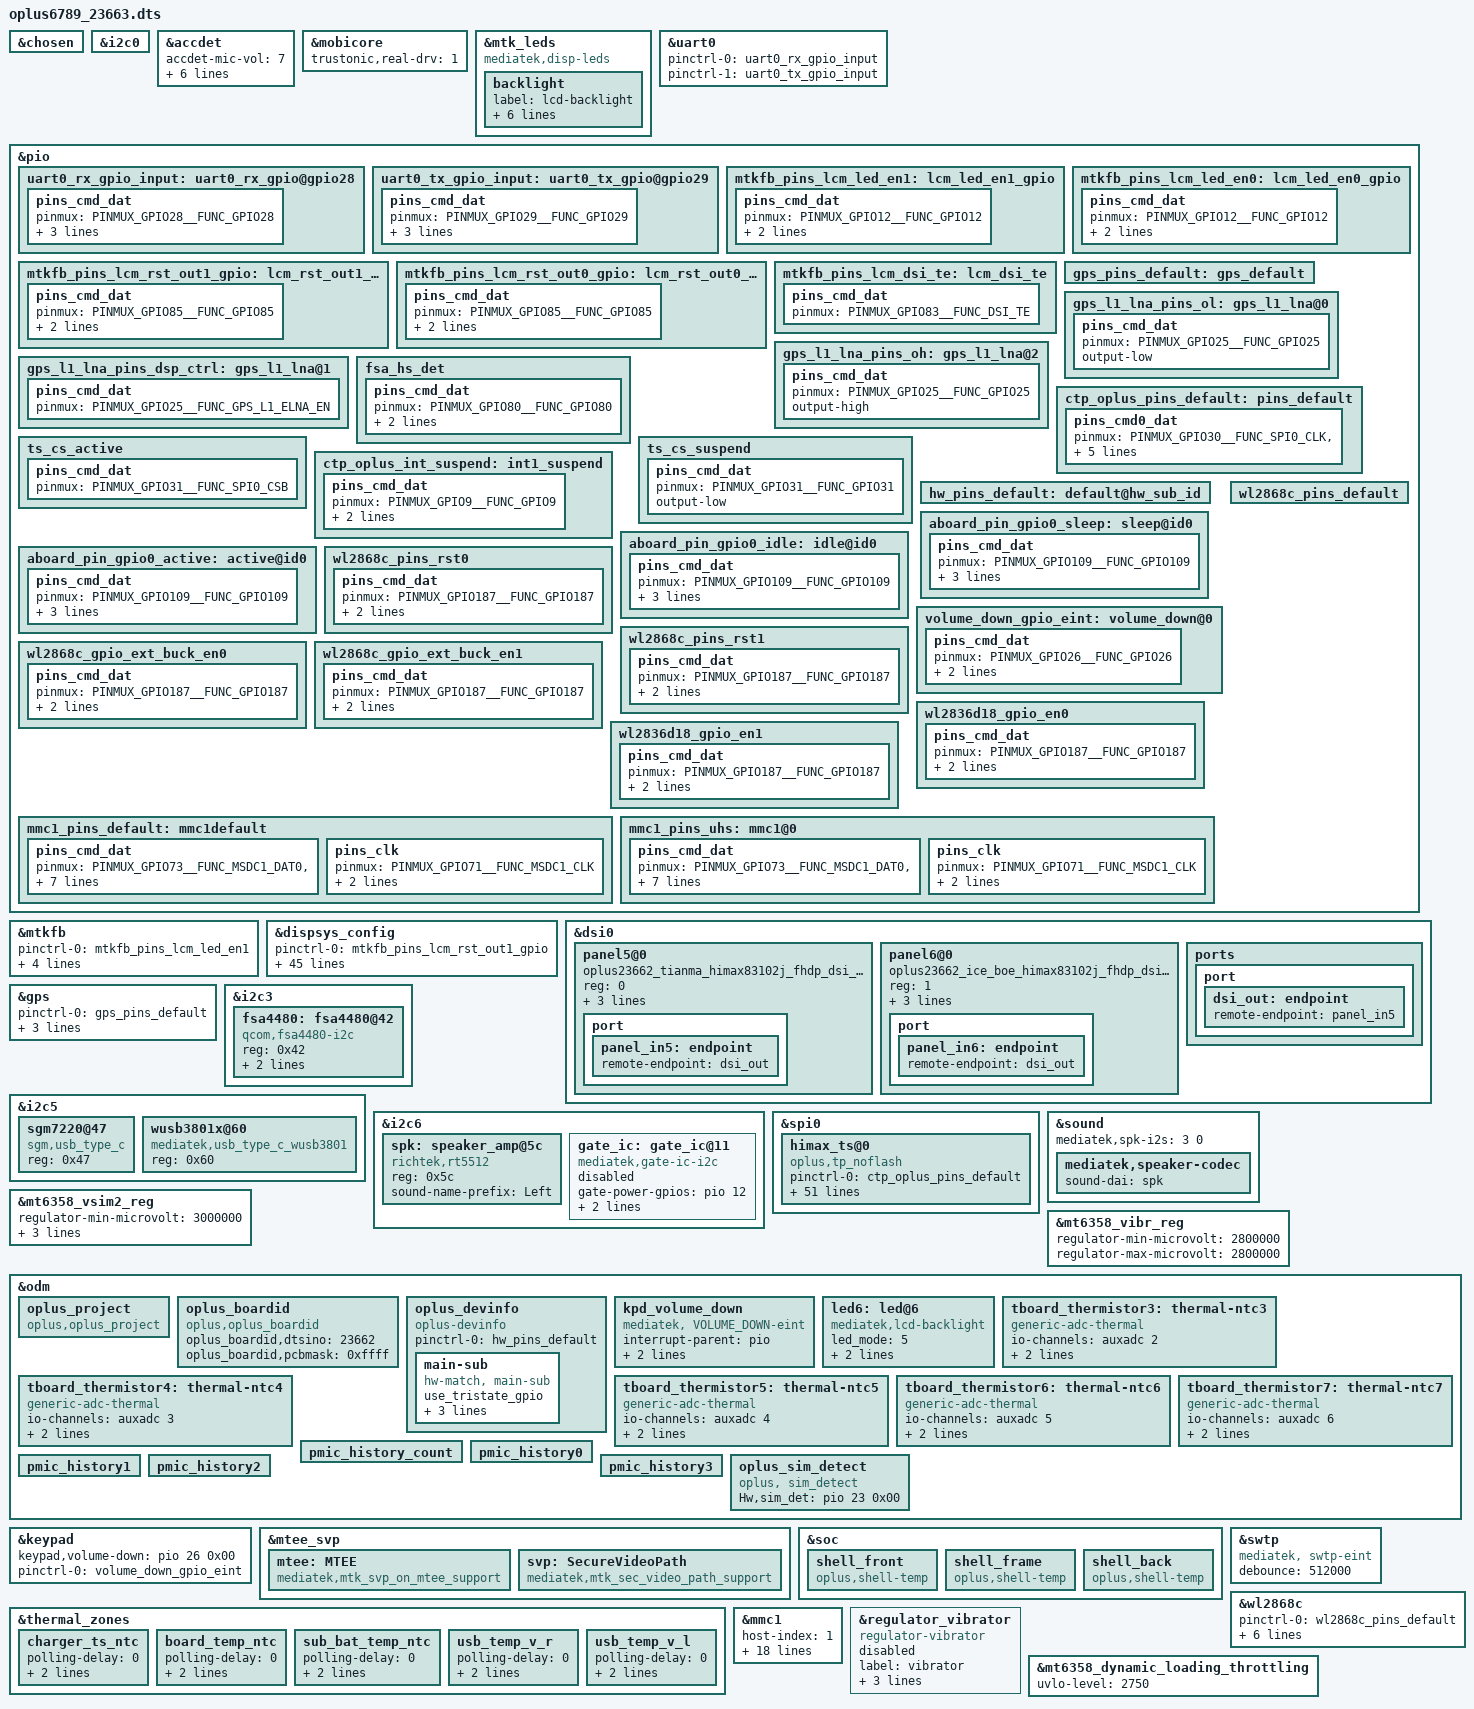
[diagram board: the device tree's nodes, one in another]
// SPDX-License-Identifier: (GPL-2.0 OR MIT)
/*
 * Copyright (C) 2021 MediaTek Inc.
 */
/dts-v1/;
/plugin/;
#include <dt-bindings/interrupt-controller/arm-gic.h>
#include <dt-bindings/interrupt-controller/irq.h>
#include <dt-bindings/pinctrl/mt6789-pinfunc.h>
#include "mediatek/cust_mt6789_camera_sonic.dtsi"
#include "mediatek/mt6789-sia810x.dtsi"
#include "mediatek/oplus6789_charger_23662.dtsi"
#include "mediatek/oplus_sensor_23662.dtsi"

&chosen {

};

&i2c0 {
	status = "okay";

};

/* accdet start */
&accdet {
    /* accdet micbias voltage: 0x07,2.7v;0x05,2.5v;0x02,1.9v */
    accdet-mic-vol = <7>;
    /* accdet pwm_width, pwm_thresh, fall_delay, rise_delay
     * debounce0, debounce1, debounce3, debounce4
     * eint pwm_width, eint pwm_thresh
     * eint deb(debounce0, debounce1, debounce2, debounce3), inv_debounce
     */
    headset-mode-setting = <0x500 0x500 1 0x1f0
                0x800 0x800 0x20 0x44
                0x4 0x1
                0x5 0x3 0x3 0x5 0xe>;
    accdet-plugout-debounce = <1>;
    /*0--MD_MAX--UP_MAX--DW_MAX*/
    headset-three-key-threshold = <0 82 170 400>;
    headset-three-key-threshold-CDD = <0 121 192 600>;
    /*0--MD_MAX--VOICE_MAX--UP_MAX--DW_MAX*/
    headset-four-key-threshold = <0 58 121 192 400>;
    status = "okay";
};
/* accdet end */

/*start tee*/
&mobicore {
	trustonic,real-drv = <1>;
};
/*end tee*/

&mtk_leds {
	compatible = "mediatek,disp-leds";
	backlight {
		label = "lcd-backlight";
		led_mode = <4>;
		max-brightness = <4095>;
		max-hw-brightness = <4095>;
		led-bits = <12>;
		trans-bits = <12>;
		default-state = "on";
	};
};

&uart0 {
	pinctrl-names = "uart0_rx_gpio",
		"uart0_tx_gpio";
	pinctrl-0 = <&uart0_rx_gpio_input>;
	pinctrl-1 = <&uart0_tx_gpio_input>;
	status = "okay";
};

&pio {
	uart0_rx_gpio_input:uart0_rx_gpio@gpio28 {
		pins_cmd_dat {
			pinmux = <PINMUX_GPIO28__FUNC_GPIO28>;
			input-enable;
			slew-rate = <0>;
			bias-pull-down;
		};
	};

	uart0_tx_gpio_input:uart0_tx_gpio@gpio29 {
		pins_cmd_dat {
			pinmux = <PINMUX_GPIO29__FUNC_GPIO29>;
			input-enable;
			slew-rate = <0>;
			bias-pull-down;
		};
	};
};

&pio {
	mtkfb_pins_lcm_led_en1: lcm_led_en1_gpio {
		pins_cmd_dat {
			pinmux = <PINMUX_GPIO12__FUNC_GPIO12>;
			slew-rate = <1>;
			output-high;
		};
	};

	mtkfb_pins_lcm_led_en0: lcm_led_en0_gpio {
		pins_cmd_dat {
			pinmux = <PINMUX_GPIO12__FUNC_GPIO12>;
			slew-rate = <1>;
			output-low;
		};
	};

	mtkfb_pins_lcm_rst_out1_gpio: lcm_rst_out1_gpio {
		pins_cmd_dat {
			pinmux = <PINMUX_GPIO85__FUNC_GPIO85>;
			slew-rate = <1>;
			output-high;
		};
	};

	mtkfb_pins_lcm_rst_out0_gpio: lcm_rst_out0_gpio {
		pins_cmd_dat {
			pinmux = <PINMUX_GPIO85__FUNC_GPIO85>;
			slew-rate = <1>;
			output-low;
		};
	};
	mtkfb_pins_lcm_dsi_te: lcm_dsi_te {
		pins_cmd_dat {
			pinmux = <PINMUX_GPIO83__FUNC_DSI_TE>;
		};
	};
};

&mtkfb {
	pinctrl-names = "lcm_led_en1_gpio", "lcm_led_en0_gpio",
		"lcm_rst_out1_gpio", "lcm_rst_out0_gpio",
		"mode_te_te";
	pinctrl-0 = <&mtkfb_pins_lcm_led_en1>;
	pinctrl-1 = <&mtkfb_pins_lcm_led_en0>;
	pinctrl-2 = <&mtkfb_pins_lcm_rst_out1_gpio>;
	pinctrl-3 = <&mtkfb_pins_lcm_rst_out0_gpio>;
	pinctrl-4 = <&mtkfb_pins_lcm_dsi_te>;
	status = "okay";
};

&dispsys_config {
	pinctrl-names =
		"lcm_rst_out1_gpio", "lcm_rst_out0_gpio",
		"mode_te_te";
	pinctrl-0 = <&mtkfb_pins_lcm_rst_out1_gpio>;
	pinctrl-1 = <&mtkfb_pins_lcm_rst_out0_gpio>;
	pinctrl-2 = <&mtkfb_pins_lcm_dsi_te>;
	status = "okay";

    helper-name = "MTK_DRM_OPT_STAGE",
            "MTK_DRM_OPT_USE_CMDQ",
            "MTK_DRM_OPT_USE_M4U",
            "MTK_DRM_OPT_MMQOS_SUPPORT",
            "MTK_DRM_OPT_MMDVFS_SUPPORT",
            "MTK_DRM_OPT_SODI_SUPPORT",
            "MTK_DRM_OPT_IDLE_MGR",
            "MTK_DRM_OPT_IDLEMGR_SWTCH_DECOUPLE",
            "MTK_DRM_OPT_IDLEMGR_BY_REPAINT",
            "MTK_DRM_OPT_IDLEMGR_ENTER_ULPS",
            "MTK_DRM_OPT_IDLEMGR_KEEP_LP11",
            "MTK_DRM_OPT_DYNAMIC_RDMA_GOLDEN_SETTING",
            "MTK_DRM_OPT_IDLEMGR_DISABLE_ROUTINE_IRQ",
            "MTK_DRM_OPT_MET_LOG",
            "MTK_DRM_OPT_USE_PQ",
            "MTK_DRM_OPT_ESD_CHECK_RECOVERY",
            "MTK_DRM_OPT_ESD_CHECK_SWITCH",
            "MTK_DRM_OPT_PRESENT_FENCE",
            "MTK_DRM_OPT_RDMA_UNDERFLOW_AEE",
            "MTK_DRM_OPT_DSI_UNDERRUN_AEE",
            "MTK_DRM_OPT_HRT",
            "MTK_DRM_OPT_HRT_MODE",
            "MTK_DRM_OPT_DELAYED_TRIGGER",
            "MTK_DRM_OPT_OVL_EXT_LAYER",
            "MTK_DRM_OPT_AOD",
            "MTK_DRM_OPT_RPO",
            "MTK_DRM_OPT_DUAL_PIPE",
            "MTK_DRM_OPT_PAPER_MODE",
            "MTK_DRM_OPT_DC_BY_HRT",
            "MTK_DRM_OPT_OVL_WCG",
            "MTK_DRM_OPT_OVL_SBCH",
            "MTK_DRM_OPT_COMMIT_NO_WAIT_VBLANK",
            "MTK_DRM_OPT_MET",
            "MTK_DRM_OPT_REG_PARSER_RAW_DUMP",
            "MTK_DRM_OPT_VP_PQ",
            "MTK_DRM_OPT_GAME_PQ",
            "MTK_DRM_OPT_MMPATH",
            "MTK_DRM_OPT_HBM",
            "MTK_DRM_OPT_VDS_PATH_SWITCH",
            "MTK_DRM_OPT_LAYER_REC",
            "MTK_DRM_OPT_CLEAR_LAYER",
            "MTK_DRM_OPT_LFR",
            "MTK_DRM_OPT_SF_PF",
            "MTK_DRM_OPT_DYN_MIPI_CHANGE",
            "MTK_DRM_OPT_PRIM_DUAL_PIPE",
            "MTK_DRM_OPT_MSYNC2_0",
            "MTK_DRM_OPT_VIRTUAL_DISP",
            "MTK_DRM_OPT_MML_PRIMARY";

    helper-value = <0>, /*MTK_DRM_OPT_STAGE*/
            <1>, /*MTK_DRM_OPT_USE_CMDQ*/
            <1>, /*MTK_DRM_OPT_USE_M4U*/
            <1>, /*MTK_DRM_OPT_MMQOS_SUPPORT*/
            <1>, /*MTK_DRM_OPT_MMDVFS_SUPPORT*/
            <0>, /*MTK_DRM_OPT_SODI_SUPPORT*/
            <1>, /*MTK_DRM_OPT_IDLE_MGR*/
            <0>, /*MTK_DRM_OPT_IDLEMGR_SWTCH_DECOUPLE*/
            <1>, /*MTK_DRM_OPT_IDLEMGR_BY_REPAINT*/
            <0>, /*MTK_DRM_OPT_IDLEMGR_ENTER_ULPS*/
            <0>, /*MTK_DRM_OPT_IDLEMGR_KEEP_LP11*/
            <0>, /*MTK_DRM_OPT_DYNAMIC_RDMA_GOLDEN_SETTING*/
            <1>, /*MTK_DRM_OPT_IDLEMGR_DISABLE_ROUTINE_IRQ*/
            <0>, /*MTK_DRM_OPT_MET_LOG*/
            <1>, /*MTK_DRM_OPT_USE_PQ*/
            <1>, /*MTK_DRM_OPT_ESD_CHECK_RECOVERY*/
            <1>, /*MTK_DRM_OPT_ESD_CHECK_SWITCH*/
            <1>, /*MTK_DRM_OPT_PRESENT_FENCE*/
            <0>, /*MTK_DRM_OPT_RDMA_UNDERFLOW_AEE*/
            <1>, /*MTK_DRM_OPT_DSI_UNDERRUN_AEE*/
            <1>, /*MTK_DRM_OPT_HRT*/
            <1>, /*MTK_DRM_OPT_HRT_MODE*/
            <0>, /*MTK_DRM_OPT_DELAYED_TRIGGER*/
            <1>, /*MTK_DRM_OPT_OVL_EXT_LAYER*/
            <0>, /*MTK_DRM_OPT_AOD*/
            <1>, /*MTK_DRM_OPT_RPO*/
            <0>, /*MTK_DRM_OPT_DUAL_PIPE*/
            <1>, /*MTK_DRM_OPT_PAPER_MODE*/
            <0>, /*MTK_DRM_OPT_DC_BY_HRT*/
            <0>, /*MTK_DRM_OPT_OVL_WCG*/
            <0>, /*MTK_DRM_OPT_OVL_SBCH*/
            <1>, /*MTK_DRM_OPT_COMMIT_NO_WAIT_VBLANK*/
            <0>, /*MTK_DRM_OPT_MET*/
            <0>, /*MTK_DRM_OPT_REG_PARSER_RAW_DUMP*/
            <0>, /*MTK_DRM_OPT_VP_PQ*/
            <0>, /*MTK_DRM_OPT_GAME_PQ*/
            <0>, /*MTK_DRM_OPT_MMPATH*/
            <0>, /*MTK_DRM_OPT_HBM*/
            <0>, /*MTK_DRM_OPT_VDS_PATH_SWITCH*/
            <0>, /*MTK_DRM_OPT_LAYER_REC*/
            <1>, /*MTK_DRM_OPT_CLEAR_LAYER*/
            <1>, /*MTK_DRM_OPT_LFR*/
            <0>, /*MTK_DRM_OPT_SF_PF*/
            <1>, /*MTK_DRM_OPT_DYN_MIPI_CHANGE*/
            <0>, /*MTK_DRM_OPT_PRIM_DUAL_PIPE*/
            <0>, /*MTK_DRM_OPT_MSYNC2_0*/
            <0>, /*MTK_DRM_OPT_VIRTUAL_DISP*/
            <0>; /*MTK_DRM_OPT_MML_PRIMARY*/
};

&dsi0 {
	status = "okay";
	#address-cells = <1>;
	#size-cells = <0>;
	panel5@0 {
		compatible = "oplus23662_tianma_himax83102j_fhdp_dsi_vdo,lcm";
		reg = <0>;
		reset-gpios = <&pio 85 0>;
		bias-gpios = <&pio 150 0>,<&pio 151 0>;
		gate-ic = <4831>;
		pinctrl-names = "default";
		port {
			panel_in5: endpoint {
				remote-endpoint = <&dsi_out>;
			};
		};
	};
	panel6@0 {
		compatible = "oplus23662_ice_boe_himax83102j_fhdp_dsi_vdo,lcm";
		reg = <1>;
		reset-gpios = <&pio 85 0>;
		bias-gpios = <&pio 150 0>,<&pio 151 0>;
		gate-ic = <4831>;
		pinctrl-names = "default";
		port {
			panel_in6: endpoint {
				remote-endpoint = <&dsi_out>;
			};
		};
	};
	ports {
		port {
			dsi_out: endpoint {
				remote-endpoint = <&panel_in5>;
			};
		};
	};
};

/* GPS GPIO standardization start */
&pio {
	gps_pins_default: gps_default {
	};
	gps_l1_lna_pins_ol: gps_l1_lna@0 {
		pins_cmd_dat {
			pinmux = <PINMUX_GPIO25__FUNC_GPIO25>;
			output-low;
		};
	};
	gps_l1_lna_pins_dsp_ctrl: gps_l1_lna@1 {
		pins_cmd_dat {
			pinmux = <PINMUX_GPIO25__FUNC_GPS_L1_ELNA_EN>;
		};
	};
	gps_l1_lna_pins_oh: gps_l1_lna@2 {
		pins_cmd_dat {
			pinmux = <PINMUX_GPIO25__FUNC_GPIO25>;
			output-high;
		};
	};
};
&gps {
	pinctrl-names = "default",
		"gps_l1_lna_disable",
		"gps_l1_lna_dsp_ctrl",
		"gps_l1_lna_enable";
	pinctrl-0 = <&gps_pins_default>;
	pinctrl-1 = <&gps_l1_lna_pins_ol>;
	pinctrl-2 = <&gps_l1_lna_pins_dsp_ctrl>;
	pinctrl-3 = <&gps_l1_lna_pins_oh>;
	status = "okay";
};
/* GPS GPIO standardization end */

#include "mediatek/cust_mt6789_camera_sonic_v4l2.dtsi"

&i2c3 {
	fsa4480: fsa4480@42 {
 		compatible = "qcom,fsa4480-i2c";
 		reg = <0x42>;
 		pinctrl-names = "default";
 		pinctrl-0 = <&fsa_hs_det>;
 		fsa4480,hs-det-gpio = <&pio 80 0>;
		status = "okay";
	};
};

&i2c5 {
	sgm7220@47 {
		compatible = "sgm,usb_type_c";
		reg = <0x47>;
		status = "okay";
	};
	wusb3801x@60 {
		compatible = "mediatek,usb_type_c_wusb3801";
		reg = <0x60>;
		status = "okay";
	};
};
&i2c6 {
	spk: speaker_amp@5c {
		compatible = "richtek,rt5512";
		#sound-dai-cells = <0>;
		reg = <0x5c>;
		status = "okay";
		sound-name-prefix = "Left";
	};
};

&pio {
 	fsa_hs_det: fsa_hs_det {
 		pins_cmd_dat {
 			pinmux = <PINMUX_GPIO80__FUNC_GPIO80>;
 			slew-rate = <1>;  /*direction 0:in, 1:out*/
 			output-high;
 		};
 	};
};

#include "mediatek/oplus-23662-tp.dtsi"
&spi0 {
	status = "okay";
	#address-cells = <1>;
	#size-cells = <0>;
	himax_ts@0 {
		compatible = "oplus,tp_noflash";
		pinctrl-names = "default", "pin_cs_high","pin_cs_low";
		pinctrl-0 = <&ctp_oplus_pins_default>;
		pinctrl-1 = <&ts_cs_active>;
		pinctrl-2 = <&ts_cs_suspend &ctp_oplus_int_suspend>;
		reg = <0>;
		chip-name = "hx83102j";
		spi-max-frequency = <10000000>;
		spi-cpha;
		interrupt-parent = <&pio>;
		panel_id = <01>;
		himax,panel-coords = <0 1200 0 2000>;
		himax,display-coords = <0 1200 0 2000>;

		report_type = <1>;
		chip-num = <1>;
		irq-gpio = <&pio 9 0x2008>;
		reset-gpio = <&pio 152 0x1>;
		interrupts = <9 0x2008>;
		vid_len = <2>;
		/* tp_type = <7>;*/	/*TM*/
		touchpanel,tp-index = <0>;
		panel_type = <7 3>;  /*type:7 TIANMA */
		touchpanel,irq_need_dev_resume_time = <500>;
		touchpanel,max-num-support = <10>;
		touchpanel,tx-rx-num = <32 50>;
		touchpanel,panel-coords = <1200 2000>;
		touchpanel,display-coords = <1200 2000>;
		touchpanel,pen-panel-coords = <1200 2000>;
		touchpanel,pen-tx-rx-num = <32 50>;
		touchpanel,pen-max-pressure = <4096>;
		touchpanel,pen-max-tilt = <90 90>;
		/*touchpanel,touchmajor-limit = <0 216>;*/

		project_id = <23663>;
		platform_support_project = <23663>;
		platform_support_project_dir = <23662>;
		platform_support_project_commandline = "oplus23662_tianma_himax83102j_fhdp_dsi_vdo_drv","oplus23662_ice_boe_himax83102j_fhdp_dsi_vdo_drv";


		incell_screen;
		/*pen_support;*/
		/*irq_need_dev_resume_ok;*/
		fw_edge_limit_support;
		black_gesture_support;
		charger_pump_support;
		headset_pump_support;
		/*esd_handle_support;*/
		/*spurious_fingerprint_support;*/
		/*lcd_trigger_fp_check;*/
		black_gesture_test_support;
		noflash_support;
		/*smart_gesture_support;*/
		pressure_report_support;
		fw_update_app_support;
		game_switch_support;
		drlimit_remove_support;
		lcd_trigger_load_tp_fw_support;
		suspend_gesture_cfg;
		/*fw_update_in_probe_with_headfile;*/
		health_monitor_support;
		exception_upload_support;

		touchpanel,button-type = <4>;
		touchpanel.button-TRx = <0 0>;
	};
};

&pio {
		ctp_oplus_pins_default: pins_default {
		pins_cmd0_dat {
		pinmux = <PINMUX_GPIO30__FUNC_SPI0_CLK>,
				<PINMUX_GPIO31__FUNC_SPI0_CSB>,
				<PINMUX_GPIO32__FUNC_SPI0_MO>,
				<PINMUX_GPIO33__FUNC_SPI0_MI>;
		bias-disable;
		drive-strength = <7>;
			};
		};
	ts_cs_active: ts_cs_active {
		pins_cmd_dat {
			pinmux = <PINMUX_GPIO31__FUNC_SPI0_CSB>;
		};
	};
	ts_cs_suspend: ts_cs_suspend {
		pins_cmd_dat {
			pinmux = <PINMUX_GPIO31__FUNC_GPIO31>;
			output-low;
		};
	};
	ctp_oplus_int_suspend: int1_suspend {
		pins_cmd_dat {
			pinmux = <PINMUX_GPIO9__FUNC_GPIO9>;
			bias-disable;
			input-enable;
		};
	};

};

&sound {
	mediatek,spk-i2s = <3 0>;
	mediatek,speaker-codec {
		sound-dai = <&spk>;
	};
};

&mt6358_vsim2_reg {
	regulator-min-microvolt = <3000000>;
	regulator-max-microvolt = <3000000>;
	regulator-always-on;
	regulator-boot-on;
};

&pio {
	hw_pins_default:default@hw_sub_id {
	};
	aboard_pin_gpio0_sleep:sleep@id0 {
		pins_cmd_dat {
			pinmux = <PINMUX_GPIO109__FUNC_GPIO109>;
			slew-rate = <0>;
			bias-pull-down;
			input-enable;
		};
	};

	aboard_pin_gpio0_active:active@id0 {
		pins_cmd_dat {
			pinmux = <PINMUX_GPIO109__FUNC_GPIO109>;
			slew-rate = <0>;
			bias-pull-up;
			input-enable;
		};
	};

	aboard_pin_gpio0_idle:idle@id0 {
		pins_cmd_dat {
			pinmux = <PINMUX_GPIO109__FUNC_GPIO109>;
			slew-rate = <0>;
			bias-disable;
			input-enable;
		};
	};
};
/*#endif OPLUS_FEATURE_TP_BASIC*/

&mt6358_vibr_reg {
	regulator-min-microvolt = <2800000>;
	regulator-max-microvolt = <2800000>;
};
&odm {
/*OPLUS_BUG_STABILITY oplus project start */
	oplus_project:oplus_project {
		compatible = "oplus,oplus_project";
	};
/*endif*/

oplus_boardid:oplus_boardid {
		compatible = "oplus,oplus_boardid";
		oplus_boardid,dtsino="23662";//only one u32
		oplus_boardid,pcbmask="0xffff";//all mask 0xffff
	};

	oplus_devinfo:oplus_devinfo {
		compatible = "oplus-devinfo";
		pinctrl-names = "default", "aboard_gpio0_sleep", "aboard_gpio0_active", "aboard_gpio0_idle";
		pinctrl-0 = <&hw_pins_default>;
		main-sub {
			use_tristate_gpio;
			compatible = "hw-match, main-sub";
			aboard-gpio0 = <&pio 109 0x00>;
			aboard-patterns = <1 1 2>;	/*0[high-resistance] 1[pull-down] 2[pull-up]*/
			/*main board*/
			match-projects = <23662 23663 23664>;
		};
	};
	/*#endif OPLUS_FEATURE_TP_BASIC*/

	kpd_volume_down:kpd_volume_down {
		compatible = "mediatek, VOLUME_DOWN-eint";
		interrupt-parent = <&pio>;
		interrupts = <26 IRQ_TYPE_EDGE_FALLING 26 0>;
		debounce = <32000>;
		status = "okay";
	};

	led6:led@6 {
		compatible = "mediatek,lcd-backlight";
		led_mode = <5>;
		data = <1>;
		pwm_config = <0 1 0 0 0>;
	};
	tboard_thermistor3: thermal-ntc3 {
		compatible = "generic-adc-thermal";
		#thermal-sensor-cells = <0>;
		io-channels = <&auxadc 2>;
		io-channel-names = "sensor-channel";
		temperature-lookup-table = <
			(-40000) 1760
			(-39000) 1757
			(-38000) 1754
			(-37000) 1751
			(-36000) 1747
			(-35000) 1744
			(-34000) 1740
			(-33000) 1736
			(-32000) 1731
			(-31000) 1727
			(-30000) 1722
			(-29000) 1716
			(-28000) 1711
			(-27000) 1705
			(-26000) 1699
			(-25000) 1693
			(-24000) 1686
			(-23000) 1679
			(-22000) 1672
			(-21000) 1664
			(-20000) 1656
			(-19000) 1648
			(-18000) 1639
			(-17000) 1630
			(-16000) 1620
			(-15000) 1610
			(-14000) 1599
			(-13000) 1588
			(-12000) 1577
			(-11000) 1565
			(-10000) 1553
			(-9000) 1540
			(-8000) 1527
			(-7000) 1514
			(-6000) 1500
			(-5000) 1485
			(-4000) 1470
			(-3000) 1455
			(-2000) 1439
			(-1000) 1423
			0 1406
			1000 1389
			2000 1372
			3000 1354
			4000 1335
			5000 1317
			6000 1298
			7000 1279
			8000 1259
			9000 1239
			10000 1219
			11000 1198
			12000 1178
			13000 1157
			14000 1136
			15000 1115
			16000 1093
			17000 1072
			18000 1050
			19000 1029
			20000 1007
			21000 986
			22000 964
			23000 943
			24000 921
			25000 900
			26000 879
			27000 858
			28000 837
			29000 816
			30000 796
			31000 775
			32000 755
			33000 736
			34000 716
			35000 697
			36000 678
			37000 659
			38000 641
			39000 623
			40000 605
			41000 588
			42000 571
			43000 555
			44000 538
			45000 523
			46000 507
			47000 492
			48000 477
			49000 463
			50000 449
			51000 435
			52000 422
			53000 409
			54000 396
			55000 384
			56000 372
			57000 360
			58000 349
			59000 338
			60000 327
			61000 317
			62000 307
			63000 297
			64000 288
			65000 279
			66000 270
			67000 261
			68000 253
			69000 245
			70000 237
			71000 230
			72000 222
			73000 215
			74000 209
			75000 202
			76000 196
			77000 189
			78000 183
			79000 178
			80000 172
			81000 167
			82000 161
			83000 156
			84000 151
			85000 147
			86000 142
			87000 138
			88000 133
			89000 129
			90000 125
			91000 121
			92000 118
			93000 114
			94000 111
			95000 107
			96000 104
			97000 101
			98000 98
			99000 95
			100000 92
			101000 89
			102000 87
			103000 84
			104000 81
			105000 79
			106000 77
			107000 74
			108000 72
			109000 70
			110000 68
			111000 66
			112000 64
			113000 62
			114000 61
			115000 59
			116000 57
			117000 56
			118000 54
			119000 52
			120000 51
			121000 50
			122000 48
			123000 47
			124000 46
			125000 44>;
	};
	tboard_thermistor4: thermal-ntc4 {
		compatible = "generic-adc-thermal";
		#thermal-sensor-cells = <0>;
		io-channels = <&auxadc 3>;
		io-channel-names = "sensor-channel";
		temperature-lookup-table = <
			(-40000) 1760
			(-39000) 1757
			(-38000) 1754
			(-37000) 1751
			(-36000) 1747
			(-35000) 1744
			(-34000) 1740
			(-33000) 1736
			(-32000) 1731
			(-31000) 1727
			(-30000) 1722
			(-29000) 1716
			(-28000) 1711
			(-27000) 1705
			(-26000) 1699
			(-25000) 1693
			(-24000) 1686
			(-23000) 1679
			(-22000) 1672
			(-21000) 1664
			(-20000) 1656
			(-19000) 1648
			(-18000) 1639
			(-17000) 1630
			(-16000) 1620
			(-15000) 1610
			(-14000) 1599
			(-13000) 1588
			(-12000) 1577
			(-11000) 1565
			(-10000) 1553
			(-9000) 1540
			(-8000) 1527
			(-7000) 1514
			(-6000) 1500
			(-5000) 1485
			(-4000) 1470
			(-3000) 1455
			(-2000) 1439
			(-1000) 1423
			0 1406
			1000 1389
			2000 1372
			3000 1354
			4000 1335
			5000 1317
			6000 1298
			7000 1279
			8000 1259
			9000 1239
			10000 1219
			11000 1198
			12000 1178
			13000 1157
			14000 1136
			15000 1115
			16000 1093
			17000 1072
			18000 1050
			19000 1029
			20000 1007
			21000 986
			22000 964
			23000 943
			24000 921
			25000 900
			26000 879
			27000 858
			28000 837
			29000 816
			30000 796
			31000 775
			32000 755
			33000 736
			34000 716
			35000 697
			36000 678
			37000 659
			38000 641
			39000 623
			40000 605
			41000 588
			42000 571
			43000 555
			44000 538
			45000 523
			46000 507
			47000 492
			48000 477
			49000 463
			50000 449
			51000 435
			52000 422
			53000 409
			54000 396
			55000 384
			56000 372
			57000 360
			58000 349
			59000 338
			60000 327
			61000 317
			62000 307
			63000 297
			64000 288
			65000 279
			66000 270
			67000 261
			68000 253
			69000 245
			70000 237
			71000 230
			72000 222
			73000 215
			74000 209
			75000 202
			76000 196
			77000 189
			78000 183
			79000 178
			80000 172
			81000 167
			82000 161
			83000 156
			84000 151
			85000 147
			86000 142
			87000 138
			88000 133
			89000 129
			90000 125
			91000 121
			92000 118
			93000 114
			94000 111
			95000 107
			96000 104
			97000 101
			98000 98
			99000 95
			100000 92
			101000 89
			102000 87
			103000 84
			104000 81
			105000 79
			106000 77
			107000 74
			108000 72
			109000 70
			110000 68
			111000 66
			112000 64
			113000 62
			114000 61
			115000 59
			116000 57
			117000 56
			118000 54
			119000 52
			120000 51
			121000 50
			122000 48
			123000 47
			124000 46
			125000 44>;
	};
	tboard_thermistor5: thermal-ntc5 {
		compatible = "generic-adc-thermal";
		#thermal-sensor-cells = <0>;
		io-channels = <&auxadc 4>;
		io-channel-names = "sensor-channel";
		temperature-lookup-table = <
			(-40000) 1760
			(-39000) 1757
			(-38000) 1754
			(-37000) 1751
			(-36000) 1747
			(-35000) 1744
			(-34000) 1740
			(-33000) 1736
			(-32000) 1731
			(-31000) 1727
			(-30000) 1722
			(-29000) 1716
			(-28000) 1711
			(-27000) 1705
			(-26000) 1699
			(-25000) 1693
			(-24000) 1686
			(-23000) 1679
			(-22000) 1672
			(-21000) 1664
			(-20000) 1656
			(-19000) 1648
			(-18000) 1639
			(-17000) 1630
			(-16000) 1620
			(-15000) 1610
			(-14000) 1599
			(-13000) 1588
			(-12000) 1577
			(-11000) 1565
			(-10000) 1553
			(-9000) 1540
			(-8000) 1527
			(-7000) 1514
			(-6000) 1500
			(-5000) 1485
			(-4000) 1470
			(-3000) 1455
			(-2000) 1439
			(-1000) 1423
			0 1406
			1000 1389
			2000 1372
			3000 1354
			4000 1335
			5000 1317
			6000 1298
			7000 1279
			8000 1259
			9000 1239
			10000 1219
			11000 1198
			12000 1178
			13000 1157
			14000 1136
			15000 1115
			16000 1093
			17000 1072
			18000 1050
			19000 1029
			20000 1007
			21000 986
			22000 964
			23000 943
			24000 921
			25000 900
			26000 879
			27000 858
			28000 837
			29000 816
			30000 796
			31000 775
			32000 755
			33000 736
			34000 716
			35000 697
			36000 678
			37000 659
			38000 641
			39000 623
			40000 605
			41000 588
			42000 571
			43000 555
			44000 538
			45000 523
			46000 507
			47000 492
			48000 477
			49000 463
			50000 449
			51000 435
			52000 422
			53000 409
			54000 396
			55000 384
			56000 372
			57000 360
			58000 349
			59000 338
			60000 327
			61000 317
			62000 307
			63000 297
			64000 288
			65000 279
			66000 270
			67000 261
			68000 253
			69000 245
			70000 237
			71000 230
			72000 222
			73000 215
			74000 209
			75000 202
			76000 196
			77000 189
			78000 183
			79000 178
			80000 172
			81000 167
			82000 161
			83000 156
			84000 151
			85000 147
			86000 142
			87000 138
			88000 133
			89000 129
			90000 125
			91000 121
			92000 118
			93000 114
			94000 111
			95000 107
			96000 104
			97000 101
			98000 98
			99000 95
			100000 92
			101000 89
			102000 87
			103000 84
			104000 81
			105000 79
			106000 77
			107000 74
			108000 72
			109000 70
			110000 68
			111000 66
			112000 64
			113000 62
			114000 61
			115000 59
			116000 57
			117000 56
			118000 54
			119000 52
			120000 51
			121000 50
			122000 48
			123000 47
			124000 46
			125000 44>;
	};
	tboard_thermistor6: thermal-ntc6 {
		compatible = "generic-adc-thermal";
		#thermal-sensor-cells = <0>;
		io-channels = <&auxadc 5>;
		io-channel-names = "sensor-channel";
		temperature-lookup-table = <
			(-40000) 1760
			(-39000) 1757
			(-38000) 1754
			(-37000) 1751
			(-36000) 1747
			(-35000) 1744
			(-34000) 1740
			(-33000) 1736
			(-32000) 1731
			(-31000) 1727
			(-30000) 1722
			(-29000) 1716
			(-28000) 1711
			(-27000) 1705
			(-26000) 1699
			(-25000) 1693
			(-24000) 1686
			(-23000) 1679
			(-22000) 1672
			(-21000) 1664
			(-20000) 1656
			(-19000) 1648
			(-18000) 1639
			(-17000) 1630
			(-16000) 1620
			(-15000) 1610
			(-14000) 1599
			(-13000) 1588
			(-12000) 1577
			(-11000) 1565
			(-10000) 1553
			(-9000) 1540
			(-8000) 1527
			(-7000) 1514
			(-6000) 1500
			(-5000) 1485
			(-4000) 1470
			(-3000) 1455
			(-2000) 1439
			(-1000) 1423
			0 1406
			1000 1389
			2000 1372
			3000 1354
			4000 1335
			5000 1317
			6000 1298
			7000 1279
			8000 1259
			9000 1239
			10000 1219
			11000 1198
			12000 1178
			13000 1157
			14000 1136
			15000 1115
			16000 1093
			17000 1072
			18000 1050
			19000 1029
			20000 1007
			21000 986
			22000 964
			23000 943
			24000 921
			25000 900
			26000 879
			27000 858
			28000 837
			29000 816
			30000 796
			31000 775
			32000 755
			33000 736
			34000 716
			35000 697
			36000 678
			37000 659
			38000 641
			39000 623
			40000 605
			41000 588
			42000 571
			43000 555
			44000 538
			45000 523
			46000 507
			47000 492
			48000 477
			49000 463
			50000 449
			51000 435
			52000 422
			53000 409
			54000 396
			55000 384
			56000 372
			57000 360
			58000 349
			59000 338
			60000 327
			61000 317
			62000 307
			63000 297
			64000 288
			65000 279
			66000 270
			67000 261
			68000 253
			69000 245
			70000 237
			71000 230
			72000 222
			73000 215
			74000 209
			75000 202
			76000 196
			77000 189
			78000 183
			79000 178
			80000 172
			81000 167
			82000 161
			83000 156
			84000 151
			85000 147
			86000 142
			87000 138
			88000 133
			89000 129
			90000 125
			91000 121
			92000 118
			93000 114
			94000 111
			95000 107
			96000 104
			97000 101
			98000 98
			99000 95
			100000 92
			101000 89
			102000 87
			103000 84
			104000 81
			105000 79
			106000 77
			107000 74
			108000 72
			109000 70
			110000 68
			111000 66
			112000 64
			113000 62
			114000 61
			115000 59
			116000 57
			117000 56
			118000 54
			119000 52
			120000 51
			121000 50
			122000 48
			123000 47
			124000 46
			125000 44>;
	};
	tboard_thermistor7: thermal-ntc7 {
		compatible = "generic-adc-thermal";
		#thermal-sensor-cells = <0>;
		io-channels = <&auxadc 6>;
		io-channel-names = "sensor-channel";
		temperature-lookup-table = <
			(-40000) 1760
			(-39000) 1757
			(-38000) 1754
			(-37000) 1751
			(-36000) 1747
			(-35000) 1744
			(-34000) 1740
			(-33000) 1736
			(-32000) 1731
			(-31000) 1727
			(-30000) 1722
			(-29000) 1716
			(-28000) 1711
			(-27000) 1705
			(-26000) 1699
			(-25000) 1693
			(-24000) 1686
			(-23000) 1679
			(-22000) 1672
			(-21000) 1664
			(-20000) 1656
			(-19000) 1648
			(-18000) 1639
			(-17000) 1630
			(-16000) 1620
			(-15000) 1610
			(-14000) 1599
			(-13000) 1588
			(-12000) 1577
			(-11000) 1565
			(-10000) 1553
			(-9000) 1540
			(-8000) 1527
			(-7000) 1514
			(-6000) 1500
			(-5000) 1485
			(-4000) 1470
			(-3000) 1455
			(-2000) 1439
			(-1000) 1423
			0 1406
			1000 1389
			2000 1372
			3000 1354
			4000 1335
			5000 1317
			6000 1298
			7000 1279
			8000 1259
			9000 1239
			10000 1219
			11000 1198
			12000 1178
			13000 1157
			14000 1136
			15000 1115
			16000 1093
			17000 1072
			18000 1050
			19000 1029
			20000 1007
			21000 986
			22000 964
			23000 943
			24000 921
			25000 900
			26000 879
			27000 858
			28000 837
			29000 816
			30000 796
			31000 775
			32000 755
			33000 736
			34000 716
			35000 697
			36000 678
			37000 659
			38000 641
			39000 623
			40000 605
			41000 588
			42000 571
			43000 555
			44000 538
			45000 523
			46000 507
			47000 492
			48000 477
			49000 463
			50000 449
			51000 435
			52000 422
			53000 409
			54000 396
			55000 384
			56000 372
			57000 360
			58000 349
			59000 338
			60000 327
			61000 317
			62000 307
			63000 297
			64000 288
			65000 279
			66000 270
			67000 261
			68000 253
			69000 245
			70000 237
			71000 230
			72000 222
			73000 215
			74000 209
			75000 202
			76000 196
			77000 189
			78000 183
			79000 178
			80000 172
			81000 167
			82000 161
			83000 156
			84000 151
			85000 147
			86000 142
			87000 138
			88000 133
			89000 129
			90000 125
			91000 121
			92000 118
			93000 114
			94000 111
			95000 107
			96000 104
			97000 101
			98000 98
			99000 95
			100000 92
			101000 89
			102000 87
			103000 84
			104000 81
			105000 79
			106000 77
			107000 74
			108000 72
			109000 70
			110000 68
			111000 66
			112000 64
			113000 62
			114000 61
			115000 59
			116000 57
			117000 56
			118000 54
			119000 52
			120000 51
			121000 50
			122000 48
			123000 47
			124000 46
			125000 44>;
	};

	pmic_history_count:pmic_history_count {
	};
	pmic_history0:pmic_history0 {
	};
	pmic_history1:pmic_history1 {
	};
	pmic_history2:pmic_history2 {
	};
	pmic_history3:pmic_history3 {
	};
};

&odm {
    oplus_sim_detect {
        compatible = "oplus, sim_detect";
        Hw,sim_det = <&pio 23 0x00>;
    };
};

&keypad {
	keypad,volume-down = <&pio 26 0x00>;
	pinctrl-names = "volume_down_as_int";
	pinctrl-0 = <&volume_down_gpio_eint>;
	status = "okay";
};
&pio {
	volume_down_gpio_eint:volume_down@0{
		pins_cmd_dat {
			pinmux = <PINMUX_GPIO26__FUNC_GPIO26>;
			slew-rate = <0>;  /*direction 0:in, 1:out*/
			input-enable;
		};
	};
};
//ifdef OPLUS_FEATURE_SECURITY_COMMON
//add for svp
&mtee_svp {
     mtee: MTEE {
         compatible = "mediatek,mtk_svp_on_mtee_support";
    };
    svp: SecureVideoPath {
        compatible = "mediatek,mtk_sec_video_path_support";
    };
};
//endif /* OPLUS_FEATURE_SECURITY_COMMON */
&thermal_zones {
	charger_ts_ntc: charger_ts_ntc {
		polling-delay = <0>; /* milliseconds */
		polling-delay-passive = <0>; /* milliseconds */
		thermal-sensors = <&tboard_thermistor7>;
	};
	board_temp_ntc: board_temp_ntc {
		polling-delay = <0>; /* milliseconds */
		polling-delay-passive = <0>; /* milliseconds */
		thermal-sensors = <&tboard_thermistor3>;
	};
	sub_bat_temp_ntc: sub_bat_temp_ntc {
		polling-delay = <0>; /* milliseconds */
		polling-delay-passive = <0>; /* milliseconds */
		thermal-sensors = <&tboard_thermistor4>;
	};
	usb_temp_v_r: usb_temp_v_r {
		polling-delay = <0>; /* milliseconds */
		polling-delay-passive = <0>; /* milliseconds */
		thermal-sensors = <&tboard_thermistor5>;
	};
	usb_temp_v_l: usb_temp_v_l {
		polling-delay = <0>; /* milliseconds */
		polling-delay-passive = <0>; /* milliseconds */
		thermal-sensors = <&tboard_thermistor6>;
	};
};

/*add for shell-temp begin*/
&soc {
	//#ifdef OPLUS_FEATURE_THERMAL_HORAE
	shell_front {
			compatible = "oplus,shell-temp";
		};
	shell_frame {
			compatible = "oplus,shell-temp";
		};
	shell_back {
			compatible = "oplus,shell-temp";
		};
	//#endif
};
/*add for shell-temp end*/

//#ifdef OPLUS_FEATURE_SWTP
&swtp {
	compatible = "mediatek, swtp-eint";
	debounce = <512000>;
};
/*endif*/

//#endif  /* OPLUS_FEATURE_SWTP */
&wl2868c {
	pinctrl-names = "default", "wl2868c_gpio_rst0", "wl2868c_gpio_rst1", "wl2868c_gpio_ext_buck_en0", "wl2868c_gpio_ext_buck_en1", "wl2836d18_gpio_en0", "wl2836d18_gpio_en1";
	pinctrl-0 = <&wl2868c_pins_default>;
	pinctrl-1 = <&wl2868c_pins_rst0>;
	pinctrl-2 = <&wl2868c_pins_rst1>;
	pinctrl-3 = <&wl2868c_gpio_ext_buck_en0>;
	pinctrl-4 = <&wl2868c_gpio_ext_buck_en1>;
	pinctrl-5 = <&wl2836d18_gpio_en0>;
	pinctrl-6 = <&wl2836d18_gpio_en1>;
	status = "okay";
};
&pio {
	wl2868c_pins_rst0: wl2868c_pins_rst0 {
		pins_cmd_dat {
			pinmux = <PINMUX_GPIO187__FUNC_GPIO187>;
			slew-rate = <1>;
			output-low;
		};
	};

	wl2868c_pins_rst1: wl2868c_pins_rst1 {
		pins_cmd_dat {
			pinmux = <PINMUX_GPIO187__FUNC_GPIO187>;
			slew-rate = <1>;
			output-high;
		};
	};

	wl2868c_gpio_ext_buck_en0: wl2868c_gpio_ext_buck_en0 {
		pins_cmd_dat {
			pinmux = <PINMUX_GPIO187__FUNC_GPIO187>;
			slew-rate = <1>;
			output-low;
		};
	};

	wl2868c_gpio_ext_buck_en1: wl2868c_gpio_ext_buck_en1 {
		pins_cmd_dat {
			pinmux = <PINMUX_GPIO187__FUNC_GPIO187>;
			slew-rate = <1>;
			output-high;
		};
	};

	wl2836d18_gpio_en0: wl2836d18_gpio_en0 {
		pins_cmd_dat {
			pinmux = <PINMUX_GPIO187__FUNC_GPIO187>;
			slew-rate = <1>;
			output-low;
		};
	};

	wl2836d18_gpio_en1: wl2836d18_gpio_en1 {
		pins_cmd_dat {
			pinmux = <PINMUX_GPIO187__FUNC_GPIO187>;
			slew-rate = <1>;
			output-high;
		};
	};

	wl2868c_pins_default: wl2868c_pins_default {
	};
};

#include <dt-bindings/gpio/gpio.h>
&mmc1 {
	host-index = <1>;
	status = "okay";
	pinctrl-names = "default", "state_uhs";
	pinctrl-0 = <&mmc1_pins_default>;
	pinctrl-1 = <&mmc1_pins_uhs>;
	bus-width = <4>;
	max-frequency = <200000000>;
	ocr-voltage = <0x00030000>;
	cap-sd-highspeed;
	sd-uhs-sdr12;
	sd-uhs-sdr25;
	sd-uhs-sdr50;
	sd-uhs-sdr104;
	sd-uhs-ddr50;
	cd-debounce-delay-ms = <0>;
	cd-gpios = <&pio 7 GPIO_ACTIVE_HIGH>;
	vmmc-supply = <&mt6358_vmch_eint_low>;
	vqmmc-supply = <&mt6358_vmc_reg>;
	no-mmc;
	dvfsrc-vcore-supply = <&dvfsrc_vcore>;
	req-vcore = <650000>;
};

&pio {
	mmc1_pins_default: mmc1default {
		pins_cmd_dat {
			pinmux = <PINMUX_GPIO73__FUNC_MSDC1_DAT0>,
				<PINMUX_GPIO74__FUNC_MSDC1_DAT1>,
				<PINMUX_GPIO75__FUNC_MSDC1_DAT2>,
				<PINMUX_GPIO76__FUNC_MSDC1_DAT3>,
				<PINMUX_GPIO72__FUNC_MSDC1_CMD>;
			input-enable;
			drive-strength = <3>;
			bias-pull-up = <MTK_PUPD_SET_R1R0_01>;
		};

		pins_clk {
			pinmux = <PINMUX_GPIO71__FUNC_MSDC1_CLK>;
			drive-strength = <3>;
			bias-pull-down = <MTK_PUPD_SET_R1R0_10>;
		};
	};
	mmc1_pins_uhs: mmc1@0{
		pins_cmd_dat {
			pinmux = <PINMUX_GPIO73__FUNC_MSDC1_DAT0>,
				<PINMUX_GPIO74__FUNC_MSDC1_DAT1>,
				<PINMUX_GPIO75__FUNC_MSDC1_DAT2>,
				<PINMUX_GPIO76__FUNC_MSDC1_DAT3>,
				<PINMUX_GPIO72__FUNC_MSDC1_CMD>;
			input-enable;
			drive-strength = <3>;
			bias-pull-up = <MTK_PUPD_SET_R1R0_01>;
		};

		pins_clk {
			pinmux = <PINMUX_GPIO71__FUNC_MSDC1_CLK>;
			drive-strength = <3>;
			bias-pull-down = <MTK_PUPD_SET_R1R0_10>;
		};
	};
};

&regulator_vibrator {
	compatible = "regulator-vibrator";
	label = "vibrator";
	min-volt = <2800000>;
	max-volt = <3500000>;
	vib-supply = <&mt6358_vibr_reg>;
	status = "disabled";
};

&mt6358_dynamic_loading_throttling {
	uvlo-level = <2750>;
};

&i2c6 {
	gate_ic: gate_ic@11 {
		compatible = "mediatek,gate-ic-i2c";
		gate-power-gpios = <&pio 12 0>;
		reg = <0x11>;
		id = <6>;
		status = "disable";
	};
};
#include <oplus6789_23662/cust.dtsi>
/*End of this file, DO NOT ADD ANYTHING HERE*/
